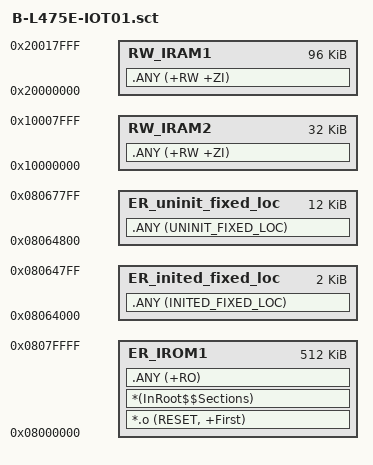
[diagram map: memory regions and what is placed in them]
; *************************************************************
; *** Scatter-Loading Description File generated by uVision ***
; *************************************************************

LR_IROM1 0x08000000 0x00080000  {    ; load region size_region
  ER_IROM1 0x08000000 0x00080000  {  ; load address = execution address
   *.o (RESET, +First)
   *(InRoot$$Sections)
   .ANY (+RO)
  }
  RW_IRAM1 0x20000000 0x00018000  {  ; RW data
   .ANY (+RW +ZI)
   }
  RW_IRAM2 0x10000000 0x00008000  {  ; RW data
   .ANY (+RW +ZI)
   }
  }
   
LR_inited_fixed_loc 0x08064000  0x800 {
   ER_inited_fixed_loc 0x08064000  0x800 {
    .ANY (INITED_FIXED_LOC)
  }
}

LR_uninit_fixed_loc 0x08064800 0x3000 {
  ER_uninit_fixed_loc 0x08064800 0x3000 {
    .ANY (UNINIT_FIXED_LOC)
  }
 }
